VERSION ""

NS_ :

BS_:

BU_: BMS MCU VCU

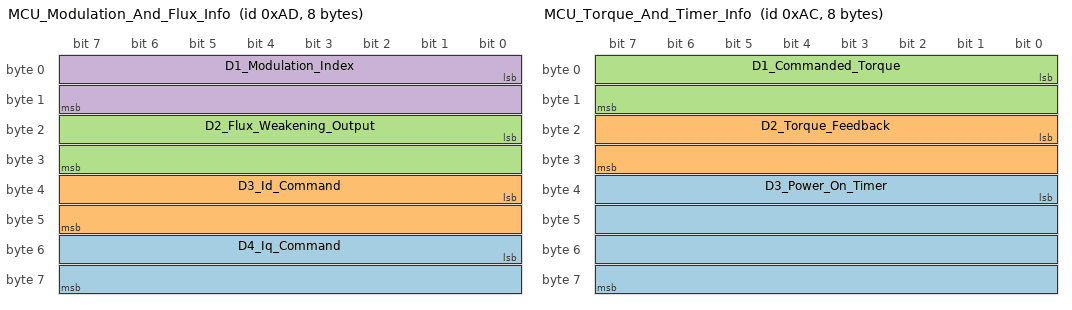
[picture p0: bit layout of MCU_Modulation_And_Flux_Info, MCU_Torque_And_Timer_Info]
BO_ 173 MCU_Modulation_And_Flux_Info: 8 MCU
 SG_ D4_Iq_Command : 48|16@1- (0.1,0) [-3276.8|3276.7] "A" Vector__XXX
 SG_ D3_Id_Command : 32|16@1- (0.1,0) [-3276.8|3276.7] "A" Vector__XXX
 SG_ D2_Flux_Weakening_Output : 16|16@1- (0.1,0) [-3276.8|3276.7] "A" Vector__XXX
 SG_ D1_Modulation_Index : 0|16@1- (0.0001,0) [-3.2768|3.2767] "" Vector__XXX

BO_ 172 MCU_Torque_And_Timer_Info: 8 MCU
 SG_ D3_Power_On_Timer : 32|32@1+ (0.003,0) [0|12884800] "Sec" Vector__XXX
 SG_ D2_Torque_Feedback : 16|16@1- (0.1,0) [-3276.8|3276.7] "Nm" Vector__XXX
 SG_ D1_Commanded_Torque : 0|16@1- (0.1,0) [-3276.8|3276.7] "Nm" Vector__XXX

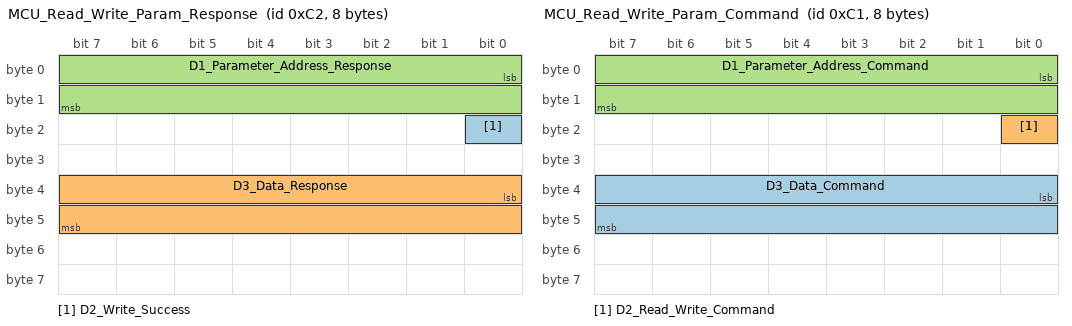
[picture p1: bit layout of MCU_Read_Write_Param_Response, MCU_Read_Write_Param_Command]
BO_ 194 MCU_Read_Write_Param_Response: 8 MCU
 SG_ D2_Write_Success : 16|1@1+ (1,0) [0|1] "" Vector__XXX
 SG_ D3_Data_Response : 32|16@1- (1,0) [-32768|32767] "" Vector__XXX
 SG_ D1_Parameter_Address_Response : 0|16@1+ (1,0) [0|65535] "" Vector__XXX

BO_ 193 MCU_Read_Write_Param_Command: 8 VCU
 SG_ D3_Data_Command : 32|16@1- (1,0) [-32768|32767] "" Vector__XXX
 SG_ D2_Read_Write_Command : 16|1@1+ (1,0) [0|1] "" Vector__XXX
 SG_ D1_Parameter_Address_Command : 0|16@1+ (1,0) [0|65535] "" Vector__XXX

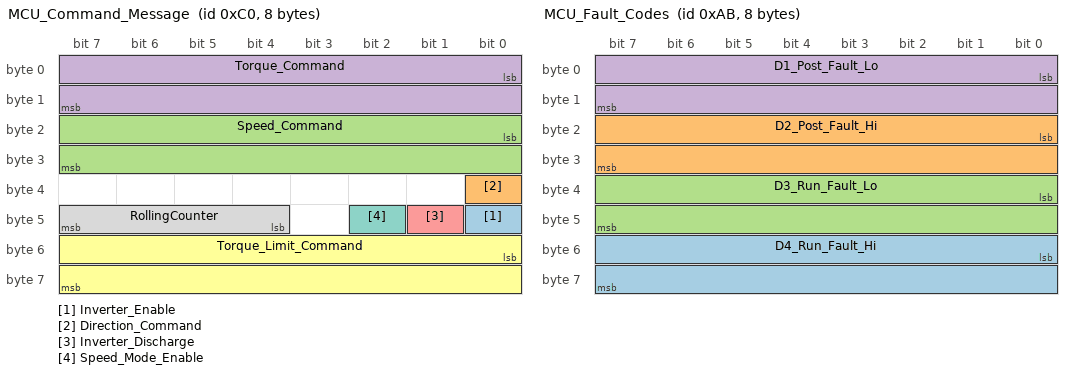
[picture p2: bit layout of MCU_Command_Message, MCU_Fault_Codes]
BO_ 192 MCU_Command_Message: 8 VCU
 SG_ Inverter_Enable : 40|1@1+ (1,0) [0|1] "Bit" Vector__XXX
 SG_ Direction_Command : 32|1@1+ (1,0) [0|1] "Bit" Vector__XXX
 SG_ Speed_Command : 16|16@1- (1,0) [-32768|32767] "rpm" Vector__XXX
 SG_ Torque_Command : 0|16@1- (0.1,0) [-3276.8|3276.7] "Nm" Vector__XXX
 SG_ Inverter_Discharge : 41|1@1+ (1,0) [0|1] "Bit" Vector__XXX
 SG_ Torque_Limit_Command : 48|16@1- (0.1,0) [-3276.8|3276.7] "Nm" Vector__XXX
 SG_ Speed_Mode_Enable : 42|1@1+ (1,0) [0|1] "Bit" Vector__XXX
 SG_ RollingCounter : 44|4@1+ (1,0) [0|15] "Bits" Vector__XXX

BO_ 171 MCU_Fault_Codes: 8 MCU
 SG_ D4_Run_Fault_Hi : 48|16@1+ (1,0) [0|65535] "" Vector__XXX
 SG_ D2_Post_Fault_Hi : 16|16@1+ (1,0) [0|65535] "" Vector__XXX
 SG_ D3_Run_Fault_Lo : 32|16@1+ (1,0) [0|65535] "" Vector__XXX
 SG_ D1_Post_Fault_Lo : 0|16@1+ (1,0) [0|65535] "" Vector__XXX

BO_ 170 MCU_Internal_States: 8 MCU
 SG_ D7_Direction_Command : 56|1@1+ (1,0) [0|1] "" Vector__XXX
 SG_ D6_Inverter_Enable_State : 48|1@1+ (1,0) [0|1] "" Vector__XXX
 SG_ D3_Relay_3_Status : 26|1@1+ (1,0) [0|1] "" Vector__XXX
 SG_ D3_Relay_4_Status : 27|1@1+ (1,0) [0|1] "" Vector__XXX
 SG_ D3_Relay_2_Status : 25|1@1+ (1,0) [0|1] "" Vector__XXX
 SG_ D4_Inverter_Run_Mode : 32|1@1+ (1,0) [0|1] "" Vector__XXX
 SG_ D5_Inverter_Command_Mode : 40|1@1+ (1,0) [0|1] "" Vector__XXX
 SG_ D3_Relay_1_Status : 24|1@1+ (1,0) [0|1] "" Vector__XXX
 SG_ D2_Inverter_State : 16|8@1+ (1,0) [0|255] "" Vector__XXX
 SG_ D1_VSM_State : 0|8@1+ (1,0) [0|15] "" Vector__XXX
 SG_ D6_Inverter_Enable_Lockout : 55|1@1+ (1,0) [0|1] "" Vector__XXX
 SG_ D4_Inverter_Discharge_State : 37|3@1+ (1,0) [0|7] "" Vector__XXX
 SG_ D3_Relay_5_Status : 28|1@1+ (1,0) [0|1] "" Vector__XXX
 SG_ D3_Relay_6_Status : 29|1@1+ (1,0) [0|1] "" Vector__XXX
 SG_ D7_BMS_Active : 57|1@1+ (1,0) [0|1] "" Vector__XXX
 SG_ D7_BMS_Torque_Limiting : 58|1@1+ (1,0) [0|1] "" Vector__XXX
 SG_ D7_Max_Speed_Limiting : 59|1@1+ (1,0) [0|1] "" Vector__XXX
 SG_ D7_Low_Speed_Limiting : 61|1@1+ (1,0) [0|1] "" Vector__XXX
 SG_ D5_Rolling_Counter : 44|4@1+ (1,0) [0|15] "" Vector__XXX
 SG_ D1_PWM_Frequency : 8|8@1+ (1,0) [0|255] "kHz" Vector__XXX
 SG_ D6_Start_Mode_Active : 54|1@1+ (1,0) [0|1] "" Vector__XXX

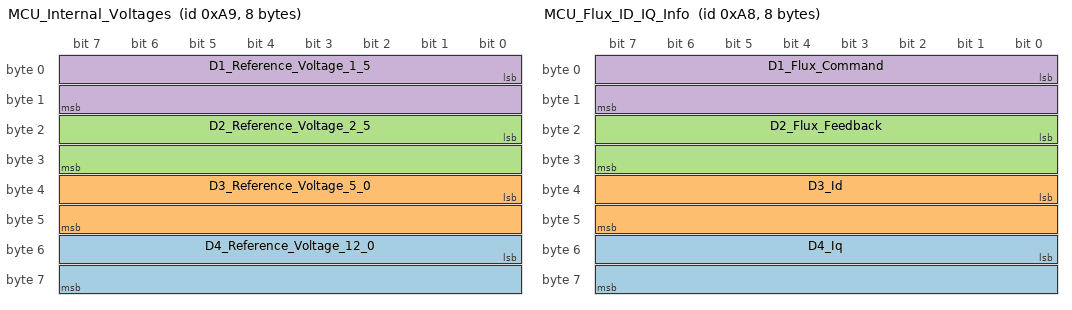
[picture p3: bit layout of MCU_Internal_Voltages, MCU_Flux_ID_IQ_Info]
BO_ 169 MCU_Internal_Voltages: 8 MCU
 SG_ D4_Reference_Voltage_12_0 : 48|16@1- (0.01,0) [-327.68|327.67] "V" Vector__XXX
 SG_ D3_Reference_Voltage_5_0 : 32|16@1- (0.01,0) [-327.68|327.67] "V" Vector__XXX
 SG_ D2_Reference_Voltage_2_5 : 16|16@1- (0.01,0) [-327.68|327.67] "V" Vector__XXX
 SG_ D1_Reference_Voltage_1_5 : 0|16@1- (0.01,0) [-327.68|327.67] "V" Vector__XXX

BO_ 168 MCU_Flux_ID_IQ_Info: 8 MCU
 SG_ D4_Iq : 48|16@1- (0.1,0) [-3276.8|3276.7] "A" Vector__XXX
 SG_ D3_Id : 32|16@1- (0.1,0) [-3276.8|3276.7] "A" Vector__XXX
 SG_ D2_Flux_Feedback : 16|16@1- (0.001,0) [-32.768|32.767] "Wb" Vector__XXX
 SG_ D1_Flux_Command : 0|16@1- (0.001,0) [-32.768|32.767] "Wb" Vector__XXX

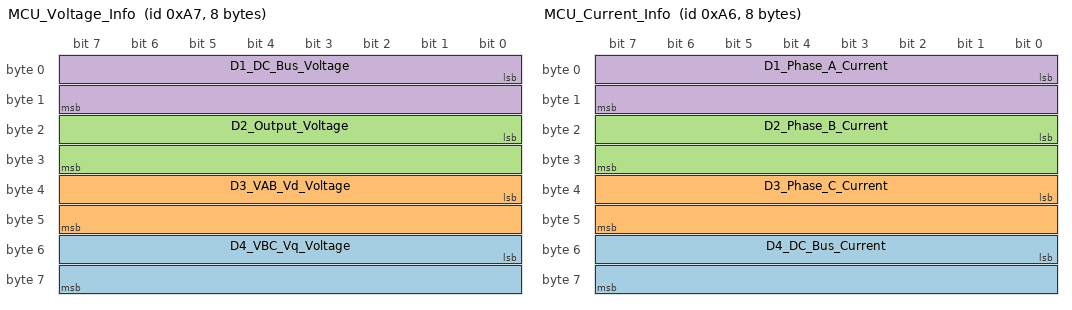
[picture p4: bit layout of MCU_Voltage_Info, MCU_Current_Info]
BO_ 167 MCU_Voltage_Info: 8 MCU
 SG_ D4_VBC_Vq_Voltage : 48|16@1- (0.1,0) [-3276.8|3276.7] "V" Vector__XXX
 SG_ D3_VAB_Vd_Voltage : 32|16@1- (0.1,0) [-3276.8|3276.7] "V" Vector__XXX
 SG_ D2_Output_Voltage : 16|16@1- (0.1,0) [-3276.8|3276.7] "V" Vector__XXX
 SG_ D1_DC_Bus_Voltage : 0|16@1- (0.1,0) [-3276.8|3276.7] "V" Vector__XXX

BO_ 166 MCU_Current_Info: 8 MCU
 SG_ D4_DC_Bus_Current : 48|16@1- (0.1,0) [-3276.8|3276.7] "A" Vector__XXX
 SG_ D3_Phase_C_Current : 32|16@1- (0.1,0) [-3276.8|3276.7] "A" Vector__XXX
 SG_ D2_Phase_B_Current : 16|16@1- (0.1,0) [-3276.8|3276.7] "A" Vector__XXX
 SG_ D1_Phase_A_Current : 0|16@1- (0.1,0) [-3276.8|3276.7] "A" Vector__XXX

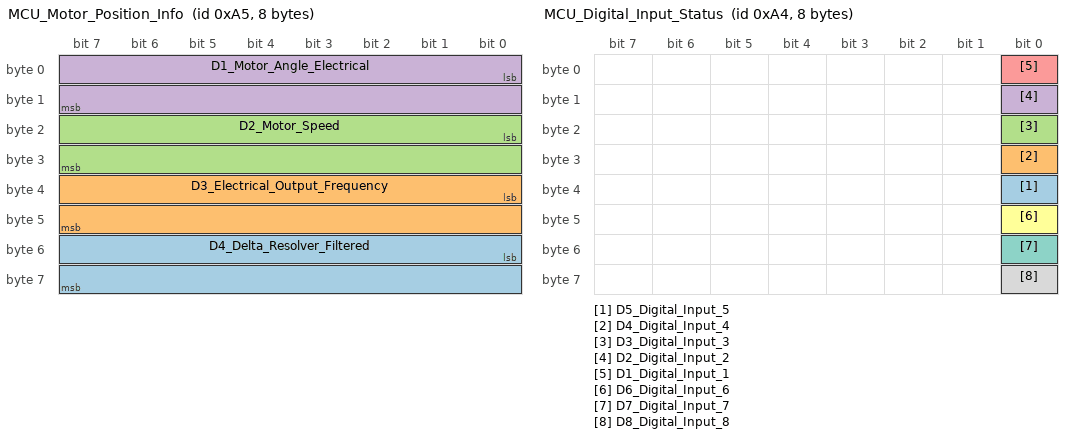
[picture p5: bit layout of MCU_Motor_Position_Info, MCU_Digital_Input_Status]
BO_ 165 MCU_Motor_Position_Info: 8 MCU
 SG_ D4_Delta_Resolver_Filtered : 48|16@1- (0.1,0) [-3276.8|3276.7] "deg" Vector__XXX
 SG_ D3_Electrical_Output_Frequency : 32|16@1- (0.1,0) [-3276.8|3276.7] "hz" Vector__XXX
 SG_ D2_Motor_Speed : 16|16@1- (1,0) [-32768|32767] "rpm" Vector__XXX
 SG_ D1_Motor_Angle_Electrical : 0|16@1+ (0.1,0) [0|6553.5] "deg" Vector__XXX

BO_ 164 MCU_Digital_Input_Status: 8 MCU
 SG_ D5_Digital_Input_5 : 32|1@1+ (1,0) [0|1] "boolean" Vector__XXX
 SG_ D4_Digital_Input_4 : 24|1@1+ (1,0) [0|1] "boolean" Vector__XXX
 SG_ D3_Digital_Input_3 : 16|1@1+ (1,0) [0|1] "boolean" Vector__XXX
 SG_ D2_Digital_Input_2 : 8|1@1+ (1,0) [0|1] "boolean" Vector__XXX
 SG_ D1_Digital_Input_1 : 0|1@1+ (1,0) [0|1] "boolean" Vector__XXX
 SG_ D6_Digital_Input_6 : 40|1@1+ (1,0) [0|1] "boolean" Vector__XXX
 SG_ D7_Digital_Input_7 : 48|1@1+ (1,0) [0|1] "boolean" Vector__XXX
 SG_ D8_Digital_Input_8 : 56|1@1+ (1,0) [0|1] "boolean" Vector__XXX

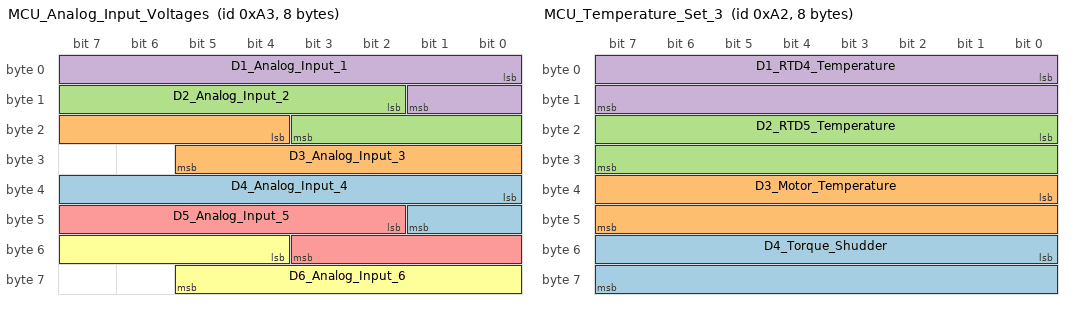
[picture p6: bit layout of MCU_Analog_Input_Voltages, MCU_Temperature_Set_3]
BO_ 163 MCU_Analog_Input_Voltages: 8 MCU
 SG_ D4_Analog_Input_4 : 32|10@1+ (0.01,0) [0|10.23] "V" Vector__XXX
 SG_ D3_Analog_Input_3 : 20|10@1+ (0.01,0) [0|10.23] "V" Vector__XXX
 SG_ D2_Analog_Input_2 : 10|10@1+ (0.01,0) [0|10.23] "V" Vector__XXX
 SG_ D1_Analog_Input_1 : 0|10@1+ (0.01,0) [0|10.23] "V" Vector__XXX
 SG_ D5_Analog_Input_5 : 42|10@1+ (0.01,0) [0|10.23] "V" Vector__XXX
 SG_ D6_Analog_Input_6 : 52|10@1+ (0.01,0) [0|10.23] "V" Vector__XXX

BO_ 162 MCU_Temperature_Set_3: 8 MCU
 SG_ D4_Torque_Shudder : 48|16@1- (0.1,0) [-3276.8|3276.7] "Nm" Vector__XXX
 SG_ D3_Motor_Temperature : 32|16@1- (0.1,0) [-3276.8|3276.7] "degC" Vector__XXX
 SG_ D2_RTD5_Temperature : 16|16@1- (0.1,0) [-3276.8|3276.7] "degC" Vector__XXX
 SG_ D1_RTD4_Temperature : 0|16@1- (0.1,0) [-3276.8|3276.7] "degC" Vector__XXX

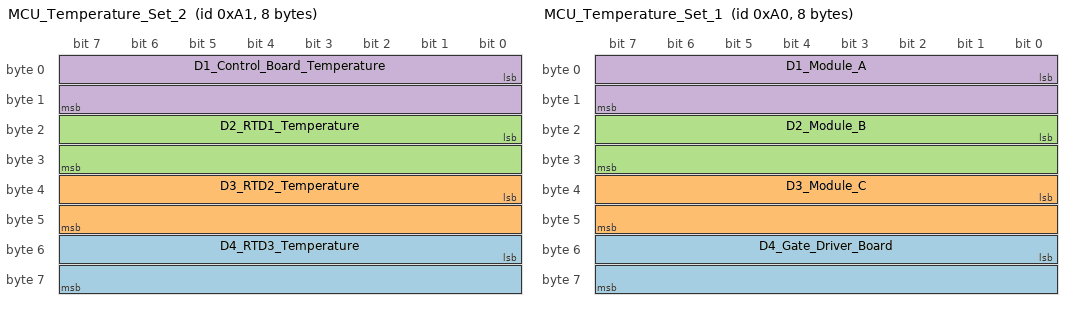
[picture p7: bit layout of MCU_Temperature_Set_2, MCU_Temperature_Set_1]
BO_ 161 MCU_Temperature_Set_2: 8 MCU
 SG_ D4_RTD3_Temperature : 48|16@1- (0.1,0) [-3276.8|3276.7] "degC" Vector__XXX
 SG_ D3_RTD2_Temperature : 32|16@1- (0.1,0) [-3276.8|3276.7] "degC" Vector__XXX
 SG_ D2_RTD1_Temperature : 16|16@1- (0.1,0) [-3276.8|3276.7] "degC" Vector__XXX
 SG_ D1_Control_Board_Temperature : 0|16@1- (0.1,0) [-3276.8|3276.7] "degC" Vector__XXX

BO_ 160 MCU_Temperature_Set_1: 8 MCU
 SG_ D4_Gate_Driver_Board : 48|16@1- (0.1,0) [-3276.8|3276.7] "degC" Vector__XXX
 SG_ D3_Module_C : 32|16@1- (0.1,0) [-3276.8|3276.7] "degC" Vector__XXX
 SG_ D2_Module_B : 16|16@1- (0.1,0) [-3276.8|3276.7] "degC" Vector__XXX
 SG_ D1_Module_A : 0|16@1- (0.1,0) [-3276.8|3276.7] "degC" Vector__XXX

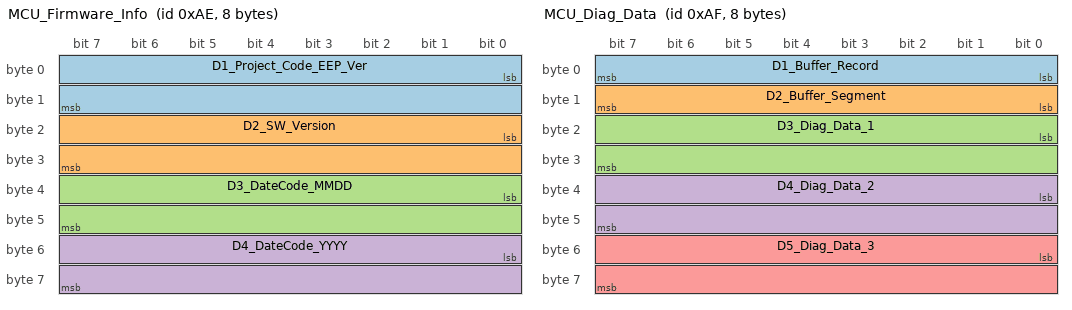
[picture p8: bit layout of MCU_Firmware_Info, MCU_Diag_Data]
BO_ 174 MCU_Firmware_Info: 8 MCU
 SG_ D1_Project_Code_EEP_Ver : 0|16@1+ (1,0) [0|65535] "" Vector__XXX
 SG_ D2_SW_Version : 16|16@1+ (1,0) [0|65535] "" Vector__XXX
 SG_ D3_DateCode_MMDD : 32|16@1+ (1,0) [0|65535] "" Vector__XXX
 SG_ D4_DateCode_YYYY : 48|16@1+ (1,0) [0|65535] "" Vector__XXX

BO_ 175 MCU_Diag_Data: 8 MCU
 SG_ D1_Buffer_Record : 0|8@1+ (1,0) [0|255] "" Vector__XXX
 SG_ D2_Buffer_Segment : 8|8@1+ (1,0) [0|5] "" Vector__XXX
 SG_ D3_Diag_Data_1 : 16|16@1- (1,0) [-32768|32767] "" Vector__XXX
 SG_ D4_Diag_Data_2 : 32|16@1- (1,0) [-32768|32767] "" Vector__XXX
 SG_ D5_Diag_Data_3 : 48|16@1- (1,0) [-32768|32767] "" Vector__XXX

BO_ 471 MCU_U2C_Command_Txd: 8 MCU
 SG_ D1_ID_Byte : 0|8@1+ (1,0) [0|255] "" Vector__XXX
 SG_ D2_Setpoint_Calc : 8|8@1+ (1,0) [0|255] "" Vector__XXX

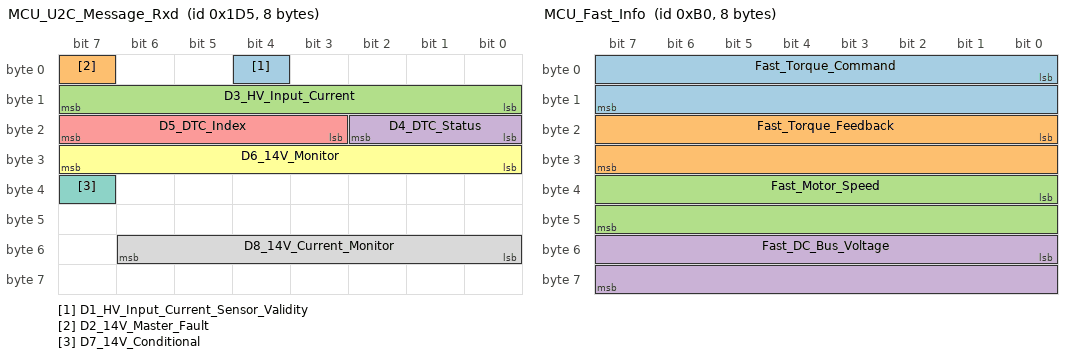
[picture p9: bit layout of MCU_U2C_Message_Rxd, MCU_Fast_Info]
BO_ 469 MCU_U2C_Message_Rxd: 8 MCU
 SG_ D1_HV_Input_Current_Sensor_Validity : 4|1@1+ (1,0) [0|1] "" Vector__XXX
 SG_ D2_14V_Master_Fault : 7|1@1+ (1,0) [0|1] "" Vector__XXX
 SG_ D3_HV_Input_Current : 8|8@1+ (1,0) [0|255] "" Vector__XXX
 SG_ D4_DTC_Status : 16|3@1+ (1,0) [0|7] "" Vector__XXX
 SG_ D5_DTC_Index : 19|5@1+ (1,0) [0|31] "" Vector__XXX
 SG_ D6_14V_Monitor : 24|8@1+ (1,0) [0|255] "" Vector__XXX
 SG_ D7_14V_Conditional : 39|1@1+ (1,0) [0|1] "" Vector__XXX
 SG_ D8_14V_Current_Monitor : 48|7@1+ (1,0) [0|127] "" Vector__XXX

BO_ 176 MCU_Fast_Info: 8 MCU
 SG_ Fast_Torque_Command : 0|16@1- (0.1,0) [-3276.8|3276.7] "Nm" Vector__XXX
 SG_ Fast_Torque_Feedback : 16|16@1- (0.1,0) [-3276.8|3276.7] "Nm" Vector__XXX
 SG_ Fast_Motor_Speed : 32|16@1- (1,0) [-32768|32767] "rpm" Vector__XXX
 SG_ Fast_DC_Bus_Voltage : 48|16@1- (0.1,0) [-3276.8|3276.7] "V" Vector__XXX

BO_ 301 VcStatus: 8 VCU
 SG_ VcStatus_VehicleState : 0|4@1+ (1,0) [0|15] "" Vector__XXX
 SG_ VcStatus_MC_ready : 5|1@1+ (1,0) [0|1] "" Vector_XXX

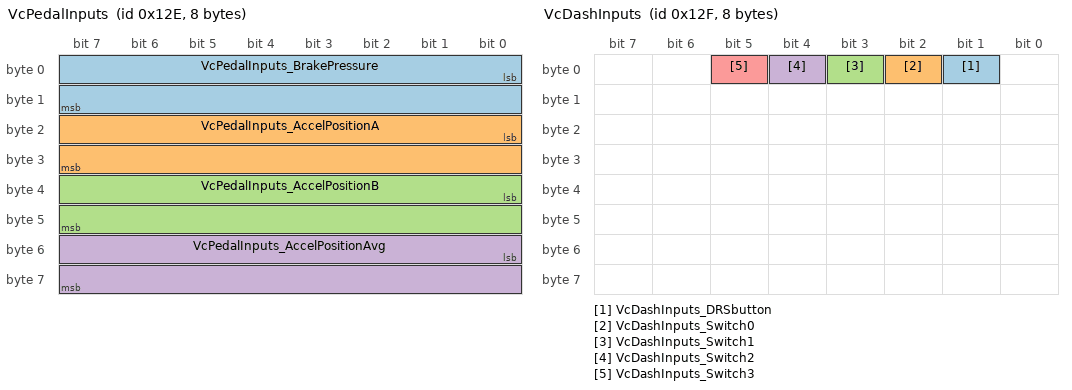
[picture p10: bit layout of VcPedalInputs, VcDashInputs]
BO_ 302 VcPedalInputs: 8 VCU
 SG_ VcPedalInputs_BrakePressure : 0|16@1+ (0.1,0) [0|3000] "psi" Vector__XXX
 SG_ VcPedalInputs_AccelPositionA : 16|16@1+ (0.1,0) [0|100] "%" Vector__XXX
 SG_ VcPedalInputs_AccelPositionB : 32|16@1+ (0.1,0) [0|100] "%" Vector__XXX
 SG_ VcPedalInputs_AccelPositionAvg : 48|16@1+ (0.1,0) [0|100] "%" Vector__XXX

BO_ 303 VcDashInputs: 8 VCU
 SG_ VcDashInputs_DRSbutton : 1|1@1+ (1,0) [0|1] "" Vector__XXX
 SG_ VcDashInputs_Switch0 : 2|1@1+ (1,0) [0|1] "" Vector__XXX
 SG_ VcDashInputs_Switch1 : 3|1@1+ (1,0) [0|1] "" Vector__XXX
 SG_ VcDashInputs_Switch2 : 4|1@1+ (1,0) [0|1] "" Vector__XXX
 SG_ VcDashInputs_Switch3 : 5|1@1+ (1,0) [0|1] "" Vector__XXX

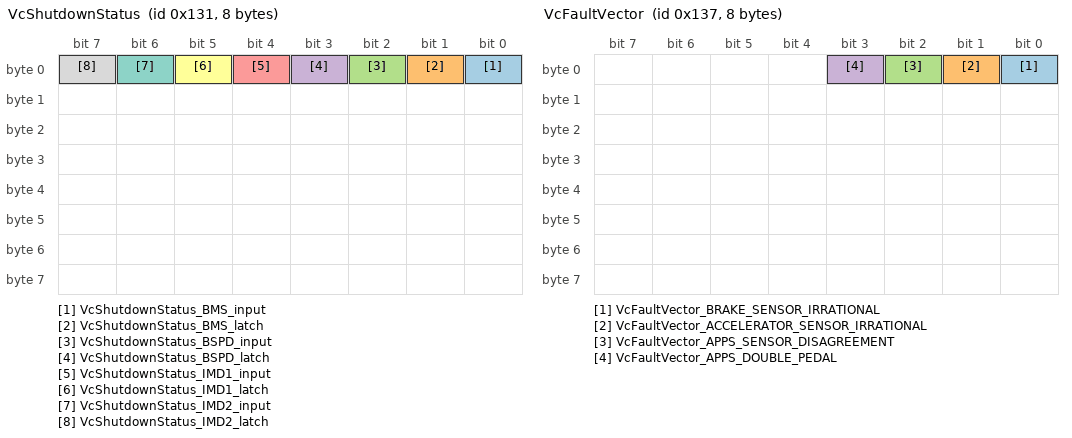
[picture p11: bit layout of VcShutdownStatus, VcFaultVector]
BO_ 305 VcShutdownStatus: 8 VCU
 SG_ VcShutdownStatus_BMS_input : 0|1@1+ (1,0) [0|1] "" Vector__XXX
 SG_ VcShutdownStatus_BMS_latch : 1|1@1+ (1,0) [0|1] "" Vector__XXX
 SG_ VcShutdownStatus_BSPD_input : 2|1@1+ (1,0) [0|1] "" Vector__XXX
 SG_ VcShutdownStatus_BSPD_latch : 3|1@1+ (1,0) [0|1] "" Vector__XXX
 SG_ VcShutdownStatus_IMD1_input : 4|1@1+ (1,0) [0|1] "" Vector__XXX
 SG_ VcShutdownStatus_IMD1_latch : 5|1@1+ (1,0) [0|1] "" Vector__XXX
 SG_ VcShutdownStatus_IMD2_input : 6|1@1+ (1,0) [0|1] "" Vector__XXX
 SG_ VcShutdownStatus_IMD2_latch : 7|1@1+ (1,0) [0|1] "" Vector__XXX

BO_ 311 VcFaultVector: 8 VCU
 SG_ VcFaultVector_BRAKE_SENSOR_IRRATIONAL: 0|1@1+ (1,0) [0|1] "" Vector__XXX
 SG_ VcFaultVector_ACCELERATOR_SENSOR_IRRATIONAL: 1|1@1+ (1,0) [0|1] "" Vector__XXX
 SG_ VcFaultVector_APPS_SENSOR_DISAGREEMENT: 2|1@1+ (1,0) [0|1] "" Vector__XXX
 SG_ VcFaultVector_APPS_DOUBLE_PEDAL: 3|1@1+ (1,0) [0|1] "" Vector__XXX

BO_ 315 VcHardFaultIndicator: 8 Vc
 SG_ VcHardFaultIndicator_task: 0|4@1+ (1,0) [0|15] "" Vector__XXX

BO_ 514 BMS_Current_Limit: 8 BMS
 SG_ D1_Max_Discharge_Current : 0|16@1+ (1,0) [0|1000] "A" Vector__XXX
 SG_ D2_Max_Charge_Current : 16|16@1+ (1,0) [0|1000] "A" Vector__XXX

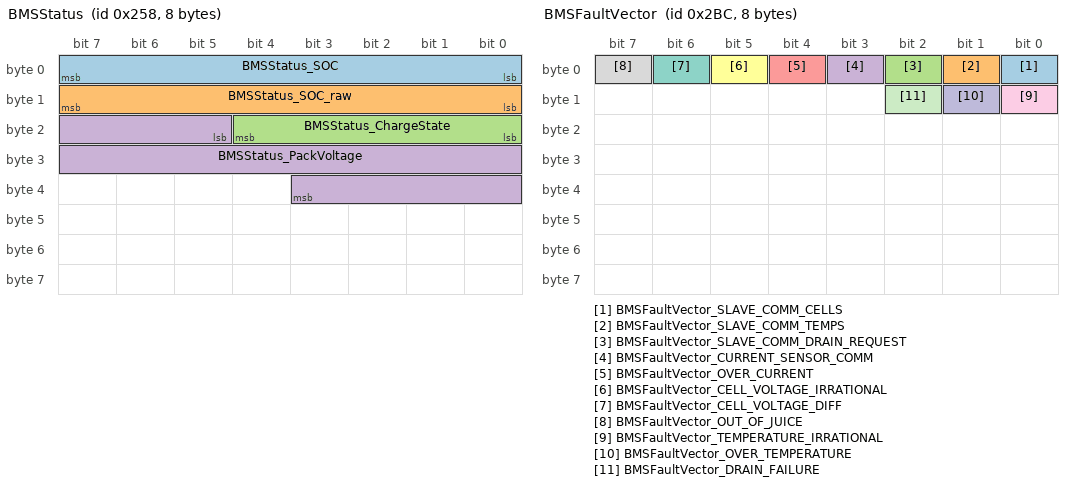
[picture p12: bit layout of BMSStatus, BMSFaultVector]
BO_ 600 BMSStatus: 8  BMS
 SG_ BMSStatus_SOC: 0|8@1+ (1,0) [0|100] "%" Vector__XXX
 SG_ BMSStatus_SOC_raw: 8|8@1+ (1,0) [0|100] "%" Vector__XXX
 SG_ BMSStatus_ChargeState: 16|5@1+ (1,0) [0|4] "" Vector__XXX
 SG_ BMSStatus_PackVoltage: 21|15@1+ (0.1,0) [0|400] "V" Vector__XXX

BO_ 700 BMSFaultVector: 8 BMS
 SG_ BMSFaultVector_SLAVE_COMM_CELLS : 0|1@1+ (1,0) [0|1] "" Vector__XXX
 SG_ BMSFaultVector_SLAVE_COMM_TEMPS : 1|1@1+ (1,0) [0|1] "" Vector__XXX
 SG_ BMSFaultVector_SLAVE_COMM_DRAIN_REQUEST : 2|1@1+ (1,0) [0|1] "" Vector__XXX
 SG_ BMSFaultVector_CURRENT_SENSOR_COMM : 3|1@1+ (1,0) [0|1] "" Vector__XXX
 SG_ BMSFaultVector_OVER_CURRENT : 4|1@1+ (1,0) [0|1] "" Vector__XXX
 SG_ BMSFaultVector_CELL_VOLTAGE_IRRATIONAL : 5|1@1+ (1,0) [0|1] "" Vector__XXX
 SG_ BMSFaultVector_CELL_VOLTAGE_DIFF : 6|1@1+ (1,0) [0|1] "" Vector__XXX
 SG_ BMSFaultVector_OUT_OF_JUICE : 7|1@1+ (1,0) [0|1] "" Vector__XXX
 SG_ BMSFaultVector_TEMPERATURE_IRRATIONAL: 8|1@1+ (1,0) [0|1] "" Vector__XXX
 SG_ BMSFaultVector_OVER_TEMPERATURE: 9|1@1+ (1,0) [0|1] "" Vector__XXX
 SG_ BMSFaultVector_DRAIN_FAILURE: 10|1@1+ (1,0) [0|1] "" Vector__XXX

BO_ 701 BMSFaultAlert: 8 BMS
 SG_ BMSFaultAlert_code M : 0|6@1+ (1,0) [0|63] "" Vector__XXX
 SG_ BMSFaultAlert_cell_comm_slave_board_num m0: 6|8@1+ (1,0) [0|255] "" Vector__XXX
 SG_ BMSFaultAlert_temp_comm_slave_board_num m1: 6|8@1+ (1,0) [0|255] "" Vector__XXX
 SG_ BMSFaultAlert_drain_comm_slave_board_num m2: 6|8@1+ (1,0) [0|255] "" Vector__XXX
 SG_ BMSFaultAlert_adc_error_code m3: 6|8@1+ (1,0) [0|255] "" Vector__XXX
 SG_ BMSFaultAlert_current m4: 6|32@1+ (0.001,0) [0|2000] "A" Vector__XXX
 SG_ BMSFaultAlert_irrational_voltage m5: 6|9@1+ (0.01,0) [0|5.12] "V" Vector__XXX
 SG_ BMSFaultAlert_voltage_diff m6: 6|9@1+ (0.01,0) [0|5.12] "V" Vector__XXX
 SG_ BMSFaultAlert_lowest_cell_voltage m7: 6|9@1+ (0.01,0) [0|5.12] "V" Vector__XXX
 SG_ BMSFaultAlert_irrational_temperature m8: 6|16@1+ (0.01,0) [-327.68|327.67] "V" Vector__XXX
 SG_ BMSFaultAlert_over_temperature m9: 6|16@1+ (0.01,0) [-327.68|327.67] "V" Vector__XXX
 SG_ BMSFaultAlert_failed_drain_cell m10: 6|8@1+ (1,0) [0|255] "" Vector__XXX

BO_ 702 BMSVoltages: 8 BMS
 SG_ BMSVoltages_mux M : 0|8@1+ (1,0) [0|255] "" Vector__XXX
 SG_ BMSVoltages_Cell0 m0 : 8|9@1+ (0.01,0) [0|5.12] "V" Vector__XXX
 SG_ BMSVoltages_Cell1 m0 : 17|9@1+ (0.01,0) [0|5.12] "V" Vector__XXX
 SG_ BMSVoltages_Cell2 m0 : 26|9@1+ (0.01,0) [0|5.12] "V" Vector__XXX
 SG_ BMSVoltages_Cell3 m0 : 35|9@1+ (0.01,0) [0|5.12] "V" Vector__XXX
 SG_ BMSVoltages_Cell4 m0 : 44|9@1+ (0.01,0) [0|5.12] "V" Vector__XXX
 SG_ BMSVoltages_Cell5 m0 : 53|9@1+ (0.01,0) [0|5.12] "V" Vector__XXX
 SG_ BMSVoltages_Cell6 m1 : 8|9@1+ (0.01,0) [0|5.12] "V" Vector__XXX
 SG_ BMSVoltages_Cell7 m1 : 17|9@1+ (0.01,0) [0|5.12] "V" Vector__XXX
 SG_ BMSVoltages_Cell8 m1 : 26|9@1+ (0.01,0) [0|5.12] "V" Vector__XXX
 SG_ BMSVoltages_Cell9 m1 : 35|9@1+ (0.01,0) [0|5.12] "V" Vector__XXX
 SG_ BMSVoltages_Cell10 m1 : 44|9@1+ (0.01,0) [0|5.12] "V" Vector__XXX
 SG_ BMSVoltages_Cell11 m1 : 53|9@1+ (0.01,0) [0|5.12] "V" Vector__XXX
 SG_ BMSVoltages_Cell12 m2 : 8|9@1+ (0.01,0) [0|5.12] "V" Vector__XXX
 SG_ BMSVoltages_Cell13 m2 : 17|9@1+ (0.01,0) [0|5.12] "V" Vector__XXX
 SG_ BMSVoltages_Cell14 m2 : 26|9@1+ (0.01,0) [0|5.12] "V" Vector__XXX
 SG_ BMSVoltages_Cell15 m2 : 35|9@1+ (0.01,0) [0|5.12] "V" Vector__XXX
 SG_ BMSVoltages_Cell16 m2 : 44|9@1+ (0.01,0) [0|5.12] "V" Vector__XXX
 SG_ BMSVoltages_Cell17 m2 : 53|9@1+ (0.01,0) [0|5.12] "V" Vector__XXX
 SG_ BMSVoltages_Cell18 m3 : 8|9@1+ (0.01,0) [0|5.12] "V" Vector__XXX
 SG_ BMSVoltages_Cell19 m3 : 17|9@1+ (0.01,0) [0|5.12] "V" Vector__XXX
 SG_ BMSVoltages_Cell20 m3 : 26|9@1+ (0.01,0) [0|5.12] "V" Vector__XXX
 SG_ BMSVoltages_Cell21 m3 : 35|9@1+ (0.01,0) [0|5.12] "V" Vector__XXX
 SG_ BMSVoltages_Cell22 m3 : 44|9@1+ (0.01,0) [0|5.12] "V" Vector__XXX
 SG_ BMSVoltages_Cell23 m3 : 53|9@1+ (0.01,0) [0|5.12] "V" Vector__XXX
 SG_ BMSVoltages_Cell24 m4 : 8|9@1+ (0.01,0) [0|5.12] "V" Vector__XXX
 SG_ BMSVoltages_Cell25 m4: 17|9@1+ (0.01,0) [0|5.12] "V" Vector__XXX
 SG_ BMSVoltages_Cell26 m4: 26|9@1+ (0.01,0) [0|5.12] "V" Vector__XXX
 SG_ BMSVoltages_Cell27 m4: 35|9@1+ (0.01,0) [0|5.12] "V" Vector__XXX
 SG_ BMSVoltages_Cell28 m4: 44|9@1+ (0.01,0) [0|5.12] "V" Vector__XXX
 SG_ BMSVoltages_Cell29 m4: 53|9@1+ (0.01,0) [0|5.12] "V" Vector__XXX
 SG_ BMSVoltages_Cell30 m5: 8|9@1+ (0.01,0) [0|5.12] "V" Vector__XXX
 SG_ BMSVoltages_Cell31 m5: 17|9@1+ (0.01,0) [0|5.12] "V" Vector__XXX
 SG_ BMSVoltages_Cell32 m5: 26|9@1+ (0.01,0) [0|5.12] "V" Vector__XXX
 SG_ BMSVoltages_Cell33 m5: 35|9@1+ (0.01,0) [0|5.12] "V" Vector__XXX
 SG_ BMSVoltages_Cell34 m5: 44|9@1+ (0.01,0) [0|5.12] "V" Vector__XXX
 SG_ BMSVoltages_Cell35 m5: 53|9@1+ (0.01,0) [0|5.12] "V" Vector__XXX
 SG_ BMSVoltages_Cell36 m6: 8|9@1+ (0.01,0) [0|5.12] "V" Vector__XXX
 SG_ BMSVoltages_Cell37 m6: 17|9@1+ (0.01,0) [0|5.12] "V" Vector__XXX
 SG_ BMSVoltages_Cell38 m6: 26|9@1+ (0.01,0) [0|5.12] "V" Vector__XXX
 SG_ BMSVoltages_Cell39 m6: 35|9@1+ (0.01,0) [0|5.12] "V" Vector__XXX
 SG_ BMSVoltages_Cell40 m6: 44|9@1+ (0.01,0) [0|5.12] "V" Vector__XXX
 SG_ BMSVoltages_Cell41 m6: 53|9@1+ (0.01,0) [0|5.12] "V" Vector__XXX
 SG_ BMSVoltages_Cell42 m7: 8|9@1+ (0.01,0) [0|5.12] "V" Vector__XXX
 SG_ BMSVoltages_Cell43 m7: 17|9@1+ (0.01,0) [0|5.12] "V" Vector__XXX
 SG_ BMSVoltages_Cell44 m7: 26|9@1+ (0.01,0) [0|5.12] "V" Vector__XXX
 SG_ BMSVoltages_Cell45 m7: 35|9@1+ (0.01,0) [0|5.12] "V" Vector__XXX
 SG_ BMSVoltages_Cell46 m7: 44|9@1+ (0.01,0) [0|5.12] "V" Vector__XXX
 SG_ BMSVoltages_Cell47 m7: 53|9@1+ (0.01,0) [0|5.12] "V" Vector__XXX
 SG_ BMSVoltages_Cell48 m8: 8|9@1+ (0.01,0) [0|5.12] "V" Vector__XXX
 SG_ BMSVoltages_Cell49 m8: 17|9@1+ (0.01,0) [0|5.12] "V" Vector__XXX
 SG_ BMSVoltages_Cell50 m8: 26|9@1+ (0.01,0) [0|5.12] "V" Vector__XXX
 SG_ BMSVoltages_Cell51 m8: 35|9@1+ (0.01,0) [0|5.12] "V" Vector__XXX
 SG_ BMSVoltages_Cell52 m8: 44|9@1+ (0.01,0) [0|5.12] "V" Vector__XXX
 SG_ BMSVoltages_Cell53 m8: 53|9@1+ (0.01,0) [0|5.12] "V" Vector__XXX
 SG_ BMSVoltages_Cell54 m9: 8|9@1+ (0.01,0) [0|5.12] "V" Vector__XXX
 SG_ BMSVoltages_Cell55 m9: 17|9@1+ (0.01,0) [0|5.12] "V" Vector__XXX
 SG_ BMSVoltages_Cell56 m9: 26|9@1+ (0.01,0) [0|5.12] "V" Vector__XXX
 SG_ BMSVoltages_Cell57 m9: 35|9@1+ (0.01,0) [0|5.12] "V" Vector__XXX
 SG_ BMSVoltages_Cell58 m9: 44|9@1+ (0.01,0) [0|5.12] "V" Vector__XXX
 SG_ BMSVoltages_Cell59 m9: 53|9@1+ (0.01,0) [0|5.12] "V" Vector__XXX
 SG_ BMSVoltages_Cell60 m10: 8|9@1+ (0.01,0) [0|5.12] "V" Vector__XXX
 SG_ BMSVoltages_Cell61 m10: 17|9@1+ (0.01,0) [0|5.12] "V" Vector__XXX
 SG_ BMSVoltages_Cell62 m10: 26|9@1+ (0.01,0) [0|5.12] "V" Vector__XXX
 SG_ BMSVoltages_Cell63 m10: 35|9@1+ (0.01,0) [0|5.12] "V" Vector__XXX
 SG_ BMSVoltages_Cell64 m10: 44|9@1+ (0.01,0) [0|5.12] "V" Vector__XXX
 SG_ BMSVoltages_Cell65 m10: 53|9@1+ (0.01,0) [0|5.12] "V" Vector__XXX
 SG_ BMSVoltages_Cell66 m11: 8|9@1+ (0.01,0) [0|5.12] "V" Vector__XXX
 SG_ BMSVoltages_Cell67 m11: 17|9@1+ (0.01,0) [0|5.12] "V" Vector__XXX
 SG_ BMSVoltages_Cell68 m11: 26|9@1+ (0.01,0) [0|5.12] "V" Vector__XXX
 SG_ BMSVoltages_Cell69 m11: 35|9@1+ (0.01,0) [0|5.12] "V" Vector__XXX
 SG_ BMSVoltages_Cell70 m11: 44|9@1+ (0.01,0) [0|5.12] "V" Vector__XXX
 SG_ BMSVoltages_Cell71 m11: 53|9@1+ (0.01,0) [0|5.12] "V" Vector__XXX
 SG_ BMSVoltages_Cell72 m12: 8|9@1+ (0.01,0) [0|5.12] "V" Vector__XXX
 SG_ BMSVoltages_Cell73 m12: 17|9@1+ (0.01,0) [0|5.12] "V" Vector__XXX
 SG_ BMSVoltages_Cell74 m12: 26|9@1+ (0.01,0) [0|5.12] "V" Vector__XXX
 SG_ BMSVoltages_Cell75 m12: 35|9@1+ (0.01,0) [0|5.12] "V" Vector__XXX
 SG_ BMSVoltages_Cell76 m12: 44|9@1+ (0.01,0) [0|5.12] "V" Vector__XXX
 SG_ BMSVoltages_Cell77 m12: 53|9@1+ (0.01,0) [0|5.12] "V" Vector__XXX
 SG_ BMSVoltages_Cell78 m13: 8|9@1+ (0.01,0) [0|5.12] "V" Vector__XXX
 SG_ BMSVoltages_Cell79 m13: 17|9@1+ (0.01,0) [0|5.12] "V" Vector__XXX
 SG_ BMSVoltages_Cell80 m13: 26|9@1+ (0.01,0) [0|5.12] "V" Vector__XXX
 SG_ BMSVoltages_Cell81 m13: 35|9@1+ (0.01,0) [0|5.12] "V" Vector__XXX
 SG_ BMSVoltages_Cell82 m13: 44|9@1+ (0.01,0) [0|5.12] "V" Vector__XXX
 SG_ BMSVoltages_Cell83 m13: 53|9@1+ (0.01,0) [0|5.12] "V" Vector__XXX
 SG_ BMSVoltages_Cell84 m14: 8|9@1+ (0.01,0) [0|5.12] "V" Vector__XXX
 SG_ BMSVoltages_Cell85 m14: 17|9@1+ (0.01,0) [0|5.12] "V" Vector__XXX
 SG_ BMSVoltages_Cell86 m14: 26|9@1+ (0.01,0) [0|5.12] "V" Vector__XXX
 SG_ BMSVoltages_Cell87 m14: 35|9@1+ (0.01,0) [0|5.12] "V" Vector__XXX
 SG_ BMSVoltages_Cell88 m14: 44|9@1+ (0.01,0) [0|5.12] "V" Vector__XXX
 SG_ BMSVoltages_Cell89 m14: 53|9@1+ (0.01,0) [0|5.12] "V" Vector__XXX

BO_ 703 BMSThermistorVoltages: 8 BMS
 SG_ BMSThermistorVoltages_mux M : 0|2@1+ (1,0) [0|3] "" Vector__XXX
 SG_ BMSThermistorVoltages_tm0 m0: 2|9@1+ (0.01,0) [0|5.12] "V" Vector__XXX
 SG_ BMSThermistorVoltages_tm1 m0: 11|9@1+ (0.01,0) [0|5.12] "V" Vector__XXX
 SG_ BMSThermistorVoltages_tm2 m0: 20|9@1+ (0.01,0) [0|5.12] "V" Vector__XXX
 SG_ BMSThermistorVoltages_tm3 m0: 29|9@1+ (0.01,0) [0|5.12] "V" Vector__XXX
 SG_ BMSThermistorVoltages_tm4 m0: 38|9@1+ (0.01,0) [0|5.12] "V" Vector__XXX
 SG_ BMSThermistorVoltages_tm5 m0: 47|9@1+ (0.01,0) [0|5.12] "V" Vector__XXX
 SG_ BMSThermistorVoltages_tm6 m1: 2|9@1+ (0.01,0) [0|5.12] "V" Vector__XXX
 SG_ BMSThermistorVoltages_tm7 m1: 11|9@1+ (0.01,0) [0|5.12] "V" Vector__XXX
 SG_ BMSThermistorVoltages_tm8 m1: 20|9@1+ (0.01,0) [0|5.12] "V" Vector__XXX
 SG_ BMSThermistorVoltages_tm9 m1: 29|9@1+ (0.01,0) [0|5.12] "V" Vector__XXX
 SG_ BMSThermistorVoltages_tm10 m1: 38|9@1+ (0.01,0) [0|5.12] "V" Vector__XXX
 SG_ BMSThermistorVoltages_tm11 m1: 47|9@1+ (0.01,0) [0|5.12] "V" Vector__XXX
 SG_ BMSThermistorVoltages_tm12 m2: 2|9@1+ (0.01,0) [0|5.12] "V" Vector__XXX
 SG_ BMSThermistorVoltages_tm13 m2: 11|9@1+ (0.01,0) [0|5.12] "V" Vector__XXX
 SG_ BMSThermistorVoltages_tm14 m2: 20|9@1+ (0.01,0) [0|5.12] "V" Vector__XXX
 SG_ BMSThermistorVoltages_tm15 m2: 29|9@1+ (0.01,0) [0|5.12] "V" Vector__XXX
 SG_ BMSThermistorVoltages_tm16 m2: 38|9@1+ (0.01,0) [0|5.12] "V" Vector__XXX
 SG_ BMSThermistorVoltages_tm17 m2: 47|9@1+ (0.01,0) [0|5.12] "V" Vector__XXX
 SG_ BMSThermistorVoltages_tm18 m3: 2|9@1+ (0.01,0) [0|5.12] "V" Vector__XXX
 SG_ BMSThermistorVoltages_tm19 m3: 11|9@1+ (0.01,0) [0|5.12] "V" Vector__XXX

BO_ 704 BMSTemperatures: 8 BMS
 SG_ BMSTemperatures_mux M : 0|2@1+ (1,0) [0|5] "" Vector__XXX
 SG_ BMSTemperatures_0 m0: 2|8@1- (1,0) [-128|127] "C" Vector__XXX
 SG_ BMSTemperatures_1 m0: 10|8@1- (1,0) [-128|127] "C" Vector__XXX
 SG_ BMSTemperatures_2 m0: 18|8@1- (1,0) [-128|127] "C" Vector__XXX
 SG_ BMSTemperatures_3 m0: 26|8@1- (1,0) [-128|127] "C" Vector__XXX
 SG_ BMSTemperatures_4 m0: 34|8@1- (1,0) [-128|127] "C" Vector__XXX
 SG_ BMSTemperatures_5 m0: 42|8@1- (1,0) [-128|127] "C" Vector__XXX
 SG_ BMSTemperatures_6 m0: 50|8@1- (1,0) [-128|127] "C" Vector__XXX
 SG_ BMSTemperatures_7 m1: 2|8@1- (1,0) [-128|127] "C" Vector__XXX
 SG_ BMSTemperatures_8 m1: 10|8@1- (1,0) [-128|127] "C" Vector__XXX
 SG_ BMSTemperatures_9 m1: 18|8@1- (1,0) [-128|127] "C" Vector__XXX
 SG_ BMSTemperatures_10 m1: 26|8@1- (1,0) [-128|127] "C" Vector__XXX
 SG_ BMSTemperatures_11 m1: 34|8@1- (1,0) [-128|127] "C" Vector__XXX
 SG_ BMSTemperatures_12 m1: 42|8@1- (1,0) [-128|127] "C" Vector__XXX
 SG_ BMSTemperatures_13 m1: 50|8@1- (1,0) [-128|127] "C" Vector__XXX
 SG_ BMSTemperatures_14 m2: 2|8@1- (1,0) [-128|127] "C" Vector__XXX
 SG_ BMSTemperatures_15 m2: 10|8@1- (1,0) [-128|127] "C" Vector__XXX
 SG_ BMSTemperatures_16 m2: 18|8@1- (1,0) [-128|127] "C" Vector__XXX
 SG_ BMSTemperatures_17 m2: 26|8@1- (1,0) [-128|127] "C" Vector__XXX
 SG_ BMSTemperatures_18 m2: 34|8@1- (1,0) [-128|127] "C" Vector__XXX
 SG_ BMSTemperatures_19 m2: 42|8@1- (1,0) [-128|127] "C" Vector__XXX
 SG_ BMSTemperatures_20 m3: 2|8@1- (1,0) [-128|127] "C" Vector__XXX
 SG_ BMSTemperatures_21 m3: 10|8@1- (1,0) [-128|127] "C" Vector__XXX
 SG_ BMSTemperatures_22 m3: 18|8@1- (1,0) [-128|127] "C" Vector__XXX
 SG_ BMSTemperatures_23 m3: 26|8@1- (1,0) [-128|127] "C" Vector__XXX
 SG_ BMSTemperatures_24 m3: 34|8@1- (1,0) [-128|127] "C" Vector__XXX
 SG_ BMSTemperatures_25 m3: 42|8@1- (1,0) [-128|127] "C" Vector__XXX
 SG_ BMSTemperatures_26 m3: 50|8@1- (1,0) [-128|127] "C" Vector__XXX
 SG_ BMSTemperatures_27 m4: 2|8@1- (1,0) [-128|127] "C" Vector__XXX
 SG_ BMSTemperatures_28 m4: 10|8@1- (1,0) [-128|127] "C" Vector__XXX
 SG_ BMSTemperatures_29 m4: 18|8@1- (1,0) [-128|127] "C" Vector__XXX
 SG_ BMSTemperatures_30 m4: 26|8@1- (1,0) [-128|127] "C" Vector__XXX
 SG_ BMSTemperatures_31 m4: 34|8@1- (1,0) [-128|127] "C" Vector__XXX
 SG_ BMSTemperatures_32 m4: 42|8@1- (1,0) [-128|127] "C" Vector__XXX
 SG_ BMSTemperatures_33 m4: 50|8@1- (1,0) [-128|127] "C" Vector__XXX
 SG_ BMSTemperatures_34 m5: 2|8@1- (1,0) [-128|127] "C" Vector__XXX
 SG_ BMSTemperatures_35 m5: 10|8@1- (1,0) [-128|127] "C" Vector__XXX
 SG_ BMSTemperatures_36 m5: 18|8@1- (1,0) [-128|127] "C" Vector__XXX
 SG_ BMSTemperatures_37 m5: 26|8@1- (1,0) [-128|127] "C" Vector__XXX
 SG_ BMSTemperatures_38 m5: 34|8@1- (1,0) [-128|127] "C" Vector__XXX
 SG_ BMSTemperatures_39 m5: 42|8@1- (1,0) [-128|127] "C" Vector__XXX

BO_ 800 BMSDrainStatusA: 8 BMS
 SG_ BMSDrainStatusA_Cell0: 0|1@1+ (1,0) [0|1] "" Vector__XXX
 SG_ BMSDrainStatusA_Cell1: 1|1@1+ (1,0) [0|1] "" Vector__XXX
 SG_ BMSDrainStatusA_Cell2: 2|1@1+ (1,0) [0|1] "" Vector__XXX
 SG_ BMSDrainStatusA_Cell3: 3|1@1+ (1,0) [0|1] "" Vector__XXX
 SG_ BMSDrainStatusA_Cell4: 4|1@1+ (1,0) [0|1] "" Vector__XXX
 SG_ BMSDrainStatusA_Cell5: 5|1@1+ (1,0) [0|1] "" Vector__XXX
 SG_ BMSDrainStatusA_Cell6: 6|1@1+ (1,0) [0|1] "" Vector__XXX
 SG_ BMSDrainStatusA_Cell7: 7|1@1+ (1,0) [0|1] "" Vector__XXX
 SG_ BMSDrainStatusA_Cell8: 8|1@1+ (1,0) [0|1] "" Vector__XXX
 SG_ BMSDrainStatusA_Cell9: 9|1@1+ (1,0) [0|1] "" Vector__XXX
 SG_ BMSDrainStatusA_Cell10: 10|1@1+ (1,0) [0|1] "" Vector__XXX
 SG_ BMSDrainStatusA_Cell11: 11|1@1+ (1,0) [0|1] "" Vector__XXX
 SG_ BMSDrainStatusA_Cell12: 12|1@1+ (1,0) [0|1] "" Vector__XXX
 SG_ BMSDrainStatusA_Cell13: 13|1@1+ (1,0) [0|1] "" Vector__XXX
 SG_ BMSDrainStatusA_Cell14: 14|1@1+ (1,0) [0|1] "" Vector__XXX
 SG_ BMSDrainStatusA_Cell15: 15|1@1+ (1,0) [0|1] "" Vector__XXX
 SG_ BMSDrainStatusA_Cell16: 16|1@1+ (1,0) [0|1] "" Vector__XXX
 SG_ BMSDrainStatusA_Cell17: 17|1@1+ (1,0) [0|1] "" Vector__XXX
 SG_ BMSDrainStatusA_Cell18: 18|1@1+ (1,0) [0|1] "" Vector__XXX
 SG_ BMSDrainStatusA_Cell19: 19|1@1+ (1,0) [0|1] "" Vector__XXX
 SG_ BMSDrainStatusA_Cell20: 20|1@1+ (1,0) [0|1] "" Vector__XXX
 SG_ BMSDrainStatusA_Cell21: 21|1@1+ (1,0) [0|1] "" Vector__XXX
 SG_ BMSDrainStatusA_Cell22: 22|1@1+ (1,0) [0|1] "" Vector__XXX
 SG_ BMSDrainStatusA_Cell23: 23|1@1+ (1,0) [0|1] "" Vector__XXX
 SG_ BMSDrainStatusA_Cell24: 24|1@1+ (1,0) [0|1] "" Vector__XXX
 SG_ BMSDrainStatusA_Cell25: 25|1@1+ (1,0) [0|1] "" Vector__XXX
 SG_ BMSDrainStatusA_Cell26: 26|1@1+ (1,0) [0|1] "" Vector__XXX
 SG_ BMSDrainStatusA_Cell27: 27|1@1+ (1,0) [0|1] "" Vector__XXX
 SG_ BMSDrainStatusA_Cell28: 28|1@1+ (1,0) [0|1] "" Vector__XXX
 SG_ BMSDrainStatusA_Cell29: 29|1@1+ (1,0) [0|1] "" Vector__XXX
 SG_ BMSDrainStatusA_Cell30: 30|1@1+ (1,0) [0|1] "" Vector__XXX
 SG_ BMSDrainStatusA_Cell31: 31|1@1+ (1,0) [0|1] "" Vector__XXX
 SG_ BMSDrainStatusA_Cell32: 32|1@1+ (1,0) [0|1] "" Vector__XXX
 SG_ BMSDrainStatusA_Cell33: 33|1@1+ (1,0) [0|1] "" Vector__XXX
 SG_ BMSDrainStatusA_Cell34: 34|1@1+ (1,0) [0|1] "" Vector__XXX
 SG_ BMSDrainStatusA_Cell35: 35|1@1+ (1,0) [0|1] "" Vector__XXX
 SG_ BMSDrainStatusA_Cell36: 36|1@1+ (1,0) [0|1] "" Vector__XXX
 SG_ BMSDrainStatusA_Cell37: 37|1@1+ (1,0) [0|1] "" Vector__XXX
 SG_ BMSDrainStatusA_Cell38: 38|1@1+ (1,0) [0|1] "" Vector__XXX
 SG_ BMSDrainStatusA_Cell39: 39|1@1+ (1,0) [0|1] "" Vector__XXX
 SG_ BMSDrainStatusA_Cell40: 40|1@1+ (1,0) [0|1] "" Vector__XXX
 SG_ BMSDrainStatusA_Cell41: 41|1@1+ (1,0) [0|1] "" Vector__XXX
 SG_ BMSDrainStatusA_Cell42: 42|1@1+ (1,0) [0|1] "" Vector__XXX
 SG_ BMSDrainStatusA_Cell43: 43|1@1+ (1,0) [0|1] "" Vector__XXX
 SG_ BMSDrainStatusA_Cell44: 44|1@1+ (1,0) [0|1] "" Vector__XXX
 SG_ BMSDrainStatusA_Cell45: 45|1@1+ (1,0) [0|1] "" Vector__XXX
 SG_ BMSDrainStatusA_Cell46: 46|1@1+ (1,0) [0|1] "" Vector__XXX
 SG_ BMSDrainStatusA_Cell47: 47|1@1+ (1,0) [0|1] "" Vector__XXX
 SG_ BMSDrainStatusA_Cell48: 48|1@1+ (1,0) [0|1] "" Vector__XXX
 SG_ BMSDrainStatusA_Cell49: 49|1@1+ (1,0) [0|1] "" Vector__XXX
 SG_ BMSDrainStatusA_Cell50: 50|1@1+ (1,0) [0|1] "" Vector__XXX
 SG_ BMSDrainStatusA_Cell51: 51|1@1+ (1,0) [0|1] "" Vector__XXX
 SG_ BMSDrainStatusA_Cell52: 52|1@1+ (1,0) [0|1] "" Vector__XXX
 SG_ BMSDrainStatusA_Cell53: 53|1@1+ (1,0) [0|1] "" Vector__XXX
 SG_ BMSDrainStatusA_Cell54: 54|1@1+ (1,0) [0|1] "" Vector__XXX
 SG_ BMSDrainStatusA_Cell55: 55|1@1+ (1,0) [0|1] "" Vector__XXX
 SG_ BMSDrainStatusA_Cell56: 56|1@1+ (1,0) [0|1] "" Vector__XXX
 SG_ BMSDrainStatusA_Cell57: 57|1@1+ (1,0) [0|1] "" Vector__XXX
 SG_ BMSDrainStatusA_Cell58: 58|1@1+ (1,0) [0|1] "" Vector__XXX
 SG_ BMSDrainStatusA_Cell59: 59|1@1+ (1,0) [0|1] "" Vector__XXX
 SG_ BMSDrainStatusA_Cell60: 60|1@1+ (1,0) [0|1] "" Vector__XXX
 SG_ BMSDrainStatusA_Cell61: 61|1@1+ (1,0) [0|1] "" Vector__XXX
 SG_ BMSDrainStatusA_Cell62: 62|1@1+ (1,0) [0|1] "" Vector__XXX
 SG_ BMSDrainStatusA_Cell63: 63|1@1+ (1,0) [0|1] "" Vector__XXX

BO_ 801 BMSDrainStatusB: 8 BMS
 SG_ BMSDrainStatusB_Cell64: 0|1@1+ (1,0) [0|1] "" Vector__XXX
 SG_ BMSDrainStatusB_Cell65: 1|1@1+ (1,0) [0|1] "" Vector__XXX
 SG_ BMSDrainStatusB_Cell66: 2|1@1+ (1,0) [0|1] "" Vector__XXX
 SG_ BMSDrainStatusB_Cell67: 3|1@1+ (1,0) [0|1] "" Vector__XXX
 SG_ BMSDrainStatusB_Cell68: 4|1@1+ (1,0) [0|1] "" Vector__XXX
 SG_ BMSDrainStatusB_Cell69: 5|1@1+ (1,0) [0|1] "" Vector__XXX
 SG_ BMSDrainStatusB_Cell70: 6|1@1+ (1,0) [0|1] "" Vector__XXX
 SG_ BMSDrainStatusB_Cell71: 7|1@1+ (1,0) [0|1] "" Vector__XXX
 SG_ BMSDrainStatusB_Cell72: 8|1@1+ (1,0) [0|1] "" Vector__XXX
 SG_ BMSDrainStatusB_Cell73: 9|1@1+ (1,0) [0|1] "" Vector__XXX
 SG_ BMSDrainStatusB_Cell74: 10|1@1+ (1,0) [0|1] "" Vector__XXX
 SG_ BMSDrainStatusB_Cell75: 11|1@1+ (1,0) [0|1] "" Vector__XXX
 SG_ BMSDrainStatusB_Cell76: 12|1@1+ (1,0) [0|1] "" Vector__XXX
 SG_ BMSDrainStatusB_Cell77: 13|1@1+ (1,0) [0|1] "" Vector__XXX
 SG_ BMSDrainStatusB_Cell78: 14|1@1+ (1,0) [0|1] "" Vector__XXX
 SG_ BMSDrainStatusB_Cell79: 15|1@1+ (1,0) [0|1] "" Vector__XXX
 SG_ BMSDrainStatusB_Cell80: 16|1@1+ (1,0) [0|1] "" Vector__XXX
 SG_ BMSDrainStatusB_Cell81: 17|1@1+ (1,0) [0|1] "" Vector__XXX
 SG_ BMSDrainStatusB_Cell82: 18|1@1+ (1,0) [0|1] "" Vector__XXX
 SG_ BMSDrainStatusB_Cell83: 19|1@1+ (1,0) [0|1] "" Vector__XXX
 SG_ BMSDrainStatusB_Cell84: 20|1@1+ (1,0) [0|1] "" Vector__XXX
 SG_ BMSDrainStatusB_Cell85: 21|1@1+ (1,0) [0|1] "" Vector__XXX
 SG_ BMSDrainStatusB_Cell86: 22|1@1+ (1,0) [0|1] "" Vector__XXX
 SG_ BMSDrainStatusB_Cell87: 23|1@1+ (1,0) [0|1] "" Vector__XXX
 SG_ BMSDrainStatusB_Cell88: 24|1@1+ (1,0) [0|1] "" Vector__XXX
 SG_ BMSDrainStatusB_Cell89: 25|1@1+ (1,0) [0|1] "" Vector__XXX

BO_ 900 BMSCurrent: 8 BMS
 SG_ BMSInstCurrentFilt : 0|32@1- (0.001,0) [-100|250] "A" Vector__XXX

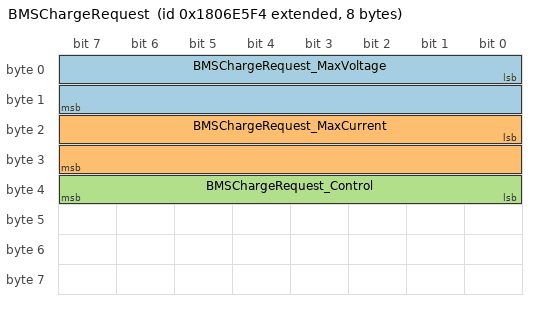
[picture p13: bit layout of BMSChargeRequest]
BO_ 2550588916 BMSChargeRequest: 8 BMS
 SG_ BMSChargeRequest_MaxVoltage: 0|16@1+ (0.1,0) [0|6553.3] "V" Vector__XXX
 SG_ BMSChargeRequest_MaxCurrent: 16|16@1+ (0.1,0) [0|6553.3] "A" Vector__XXX
 SG_ BMSChargeRequest_Control: 32|8@1+ (1,0) [0|1] "" Vector__XXX

BO_ 950 BMSHardFaultIndicator: 8 BMS
 SG_ BMSHardFaultIndicator_task: 0|4@1+ (1,0) [0|15] "" Vector__XXX

BO_ 951 BMSRef: 8 BMS
 SG_ BMSRef_mux M: 0|1@1+ (1,0) [0|1] "" Vector__XXX
 SG_ BMSRef_ref0 m0: 1|9@1+ (0.01,0) [0|5.12] "V" Vector__XXX
 SG_ BMSRef_ref1 m0: 10|9@1+ (0.01,0) [0|5.12] "V" Vector__XXX
 SG_ BMSRef_ref2 m0: 19|9@1+ (0.01,0) [0|5.12] "V" Vector__XXX
 SG_ BMSRef_ref3 m0: 28|9@1+ (0.01,0) [0|5.12] "V" Vector__XXX
 SG_ BMSRef_ref4 m0: 37|9@1+ (0.01,0) [0|5.12] "V" Vector__XXX
 SG_ BMSRef_ref5 m0: 46|9@1+ (0.01,0) [0|5.12] "V" Vector__XXX
 SG_ BMSRef_ref6 m1: 1|9@1+ (0.01,0) [0|5.12] "V" Vector__XXX
 SG_ BMSRef_ref7 m1: 10|9@1+ (0.01,0) [0|5.12] "V" Vector__XXX
 SG_ BMSRef_ref8 m1: 19|9@1+ (0.01,0) [0|5.12] "V" Vector__XXX
 SG_ BMSRef_ref9 m1: 28|9@1+ (0.01,0) [0|5.12] "V" Vector__XXX
 SG_ BMSRef_ref10 m1: 37|9@1+ (0.01,0) [0|5.12] "V" Vector__XXX
 SG_ BMSRef_ref11 m1: 46|9@1+ (0.01,0) [0|5.12] "V" Vector__XXX

CM_ BU_ BMS "Battery Management System";
CM_ BU_ MCU "Motor Control Unit";
CM_ BU_ VC "Vehicle Controller";

VAL_ 301 VcStatus_VehicleState 0 "VehicleState_NOT_READY" 1 "VehicleState_STARTUP" 2 "VehicleState_READY_TO_DRIVE" 3 "VehicleState_FAULTED";
VAL_ 701 BMSFaultAlert_code 0 "FaultCode_SLAVE_COMM_CELLS" 1 "FaultCode_SLAVE_COMM_TEMPS" 2 "FaultCode_SLAVE_COMM_DRAIN_REQUEST" 3 "FaultCode_CURRENT_SENSOR_COMM" 4 "FaultCode_OVER_CURRENT" 5 "FaultCode_CELL_VOLTAGE_IRRATIONAL" 6 "FaultCode_CELL_VOLTAGE_DIFF" 7 "Faultcode_OUT_OF_JUICE" 8 "FaultCode_TEMPERATURE_IRRATIONAL" 9 "FaultCode_OVER_TEMP" 10 "FaultCode_DRAIN_FAILURE";
VAL_ 600 BMSStatus_ChargeState 0 "ChargeState_DISCONNECTED" 1 "ChargeState_CONNECTED_COMPLETE" 2 "ChargeState_CONNECTED_BALANCING" 3 "ChargeState_CONNECTED_CHARGING" 4 "ChargeState_CONNECTED_BALANCE_SENSING";
VAL_ 950 BMSHardFaultIndicator_task 0 "unknown" 1 "task_1Hz" 2 "task_10Hz" 3 "task_1kHz" 4 "can_rx_task";
VAL_ 315 BMSHardFaultIndicator_task 0 "unknown" 1 "task_100Hz" ;

VAL_ 192 Direction_Command 0 "CW" 1 "CCW" ;
VAL_ 192 Inverter_Discharge 0 "Discharge Disable" 1 "Discharge Enable (if EEPROM parameter is set)" ;
VAL_ 170 D2_Inverter_State 0 "Power up" 1 "Stop" 2 "Open Loop" 3 "Closed Loop" 4 "Internal State" 5 "Internal State" 6 "Internal State" 7 "Internal State" 8 "Idle Run" 9 "Idle Stop" 10 "Internal State" 11 "Intern State" 12 "Internal State" ;
VAL_ 170 D1_VSM_State 0 "VSM Start State" 1 "Pre-Charge Init state" 2 "pre-charge active state" 3 "pre-charge complete state" 4 "VSM wait state" 5 "VSM ready state" 6 "Motor Running State" 7 "blink fault code state" 14 "Shutdown state for Key Switch Mode 1" 15 "Reset the inverter" ;
